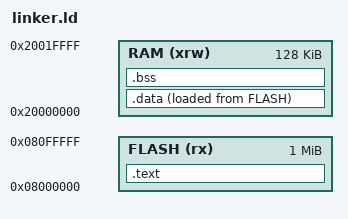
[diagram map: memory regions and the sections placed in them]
MEMORY
{
  FLASH (rx) : ORIGIN = 0x08000000, LENGTH = 1024K
  RAM (xrw)  : ORIGIN = 0x20000000, LENGTH = 128K
}

SECTIONS
{
  .text : {
    KEEP(*(.isr_vector))
    *(.text*)
    *(.rodata*)
  } > FLASH
  
  .data : { *(.data*) } > RAM AT > FLASH
  .bss : { *(.bss*) } > RAM
}
